# apollo510 register map
Vendor: Ambiq Micro; Series: Apollo; File version: 1.0
CPU: CM55 r1p1, little endian, MPU, FPU, double-precision FPU, DSP, I-cache, D-cache, VTOR, ITCM, DTCM, 4 interrupt priority bits, 0 interrupts, 8 SAU regions
Registers are 32-bit, read-write, reset 0x0 unless marked. A register's access mark holds for its fields unless they carry their own. Offsets are from the block's base; [hi:lo] are bit positions; {n}, {i} and the like mark numbered series; 'fields as' and 'values as' point back to an identical list.

## GPIO (part 7 of 7) — General Purpose IO
Base 0x40010000
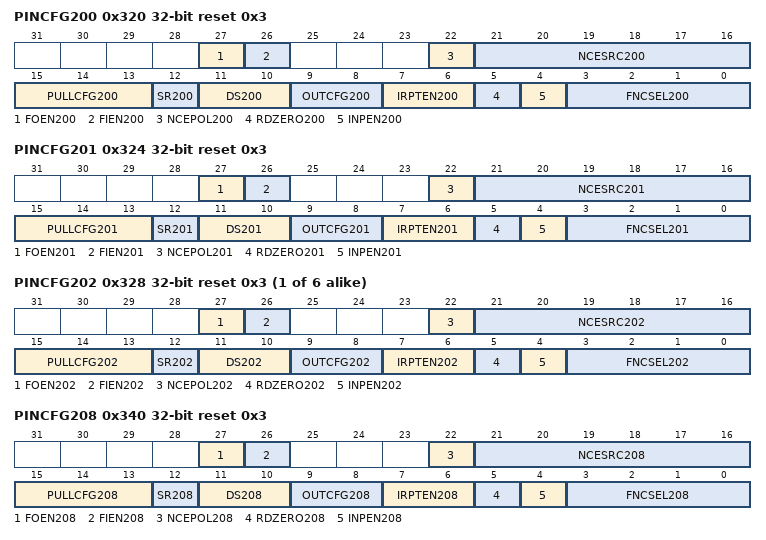
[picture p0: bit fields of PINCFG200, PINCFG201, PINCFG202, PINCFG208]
0x320 PINCFG200 reset 0x3 — Controls the operation of GPIO pin 200.
  [27] FOEN200 — Force output enable active regardless of function selected. Otherwise the selected function will enable the output only when needed
  [26] FIEN200 — Force input enable active regardless of function selected. Otherwise the selected function will enable the input only when needed
  [22] NCEPOL200 — Polarity select for NCE for GPIO 200
    0=LOW (Polarity is active low); 1=HIGH (Polarity is active high)
  [21:16] NCESRC200 — IOMSTR/MSPI N Chip Select 200, DISP control signals DE, CSX, and CS. Polarity is determined by CE_POLARITY field
    {v}=IOM0CE{v} (IOM 0 NCE {v} module) (v=0..3); {v}=IOM1CE{v-4} (IOM 1 NCE {v-4} module) (v=4..7); {v}=IOM2CE{v-8} (IOM 2 NCE {v-8} module) (v=8..11); {v}=IOM3CE{v-12} (IOM 3 NCE {v-12} module) (v=12..15); {v}=IOM4CE{v-16} (IOM 4 NCE {v-16} module) (v=16..19); {v}=IOM5CE{v-20} (IOM 5 NCE {v-20} module) (v=20..23); {v}=IOM6CE{v-24} (IOM 6 NCE {v-24} module) (v=24..27); {v}=IOM7CE{v-28} (IOM 7 NCE {v-28} module) (v=28..31); 48=DC_DPI_DE (DC DPI DE module); 49=DISP_CONT_CSX (DISP CONT CSX module); 50=DC_SPI_CS_N (DC SPI CS_N module); 51=DC_QSPI_CS_N (DC QSPI CS_N module); 52=DC_RESX (DC module RESX)
  [15:13] PULLCFG200 — Pullup/Pulldown configuration for GPIO 200
    0=DIS (No pullup or pulldown selected); 1=PD50K (50K Pulldown selected); 2=PU15K (1.5K Pullup selected); 3=PU6K (6K Pullup selected); 4=PU12K (12K Pullup selected); 5=PU24K (24K Pullup selected); 6=PU50K (50K Pullup selected); 7=PU100K (100K Pullup selected)
  [12] SR200 — Configure the slew rate
  [11:10] DS200 — Drive strength selection for GPIO 200
    0=0P1X (0.1x output driver selected); 1=0P5X (0.5x output driver selected); 2=0P75X (0.75x output driver selected); 3=1P0X (1.0x output driver selected)
  [9:8] OUTCFG200 — Pin IO mode selection for GPIO pin 200
    0=DIS (Output Disabled); 1=PUSHPULL (Output configured in push pull mode. Will drive 0 and 1 values on pin.); 2=OD (Output configured in open drain mode. Will only drive pin low, tristate otherwise.); 3=TS (Output configured in Tristate-able push pull mode. Will drive 0, 1 of HiZ on pin.)
  [7:6] IRPTEN200 — Interrupt enable for GPIO 200
    0=DIS (Interrupts are disabled for this GPIO); 1=INTFALL (Interrupts are enabled for falling edge transition on this GPIO); 2=INTRISE (Interrupts are enabled for rising edge transitions on this GPIO); 3=INTANY (Interrupts are enabled for any edge transition on this GPIO)
  [5] RDZERO200 — Return 0 for read data on GPIO 200
  [4] INPEN200 — Input enable for GPIO 200
  [3:0] FNCSEL200 — Function select for GPIO pin 200
    1=MNCE0_1 (MSPI Master 0 nCE 1 Signal); 2=MNCE0_0 (MSPI Master 0 nCE 0 Signal); 3=GPIO (General purpose I/O); 6=CT200 (Timer/Counter input or output; Selection of direction is done via CTIMER register settings.); 7=NCE200 (IOMSTR N Chip Select. Polarity is determined by CE_POLARITY field); 11=FPIO (Fast PIO)
0x324 PINCFG201 reset 0x3 — Controls the operation of GPIO pin 201.
  [27] FOEN201 — Force output enable active regardless of function selected. Otherwise the selected function will enable the output only when needed
  [26] FIEN201 — Force input enable active regardless of function selected. Otherwise the selected function will enable the input only when needed
  [22] NCEPOL201 — Polarity select for NCE for GPIO 201
    values as PINCFG200.NCEPOL200
  [21:16] NCESRC201 — IOMSTR/MSPI N Chip Select 201, DISP control signals DE, CSX, and CS. Polarity is determined by CE_POLARITY field
    values as PINCFG200.NCESRC200
  [15:13] PULLCFG201 — Pullup/Pulldown configuration for GPIO 201
    values as PINCFG200.PULLCFG200
  [12] SR201 — Configure the slew rate
  [11:10] DS201 — Drive strength selection for GPIO 201
    0=0P1X (0.1x output driver selected); 1=0P5X (0.5x output driver selected)
  [9:8] OUTCFG201 — Pin IO mode selection for GPIO pin 201
    values as PINCFG200.OUTCFG200
  [7:6] IRPTEN201 — Interrupt enable for GPIO 201
    values as PINCFG200.IRPTEN200
  [5] RDZERO201 — Return 0 for read data on GPIO 201
  [4] INPEN201 — Input enable for GPIO 201
  [3:0] FNCSEL201 — Function select for GPIO pin 201
    3=GPIO (General purpose I/O); 6=CT201 (Timer/Counter input or output; Selection of direction is done via CTIMER register settings.); 7=NCE201 (IOMSTR N Chip Select. Polarity is determined by CE_POLARITY field); 11=FPIO (Fast PIO)
{0x0+4i} PINCFG{i} reset 0x3 (i=202..207) — Controls the operation of GPIO pin {i}.
  [27] FOEN{i} — Force output enable active regardless of function selected. Otherwise the selected function will enable the output only when needed
  [26] FIEN{i} — Force input enable active regardless of function selected. Otherwise the selected function will enable the input only when needed
  [22] NCEPOL{i} — Polarity select for NCE for GPIO {i}
    values as PINCFG200.NCEPOL200
  [21:16] NCESRC{i} — IOMSTR/MSPI N Chip Select {i}, DISP control signals DE, CSX, and CS. Polarity is determined by CE_POLARITY field
    values as PINCFG200.NCESRC200
  [15:13] PULLCFG{i} — Pullup/Pulldown configuration for GPIO {i}
    values as PINCFG200.PULLCFG200
  [12] SR{i} — Configure the slew rate
  [11:10] DS{i} — Drive strength selection for GPIO {i}
    values as PINCFG201.DS201
  [9:8] OUTCFG{i} — Pin IO mode selection for GPIO pin {i}
    values as PINCFG200.OUTCFG200
  [7:6] IRPTEN{i} — Interrupt enable for GPIO {i}
    values as PINCFG200.IRPTEN200
  [5] RDZERO{i} — Return 0 for read data on GPIO {i}
  [4] INPEN{i} — Input enable for GPIO {i}
  [3:0] FNCSEL{i} — Function select for GPIO pin {i}
0x340 PINCFG208 reset 0x3 — Controls the operation of GPIO pin 208.
  [27] FOEN208 — Force output enable active regardless of function selected. Otherwise the selected function will enable the output only when needed
  [26] FIEN208 — Force input enable active regardless of function selected. Otherwise the selected function will enable the input only when needed
  [22] NCEPOL208 — Polarity select for NCE for GPIO 208
    values as PINCFG200.NCEPOL200
  [21:16] NCESRC208 — IOMSTR/MSPI N Chip Select 208, DISP control signals DE, CSX, and CS. Polarity is determined by CE_POLARITY field
    values as PINCFG200.NCESRC200
  [15:13] PULLCFG208 — Pullup/Pulldown configuration for GPIO 208
    values as PINCFG200.PULLCFG200
  [12] SR208 — Configure the slew rate
  [11:10] DS208 — Drive strength selection for GPIO 208
    values as PINCFG201.DS201
  [9:8] OUTCFG208 — Pin IO mode selection for GPIO pin 208
    values as PINCFG200.OUTCFG200
  [7:6] IRPTEN208 — Interrupt enable for GPIO 208
    values as PINCFG200.IRPTEN200
  [5] RDZERO208 — Return 0 for read data on GPIO 208
  [4] INPEN208 — Input enable for GPIO 208
  [3:0] FNCSEL208 — Function select for GPIO pin 208
    1=32KHzXT (32kHZ from analog); 3=GPIO (General purpose I/O); 6=CT208 (Timer/Counter input or output; Selection of direction is done via CTIMER register settings.); 7=NCE208 (IOMSTR N Chip Select. Polarity is determined by CE_POLARITY field); 11=FPIO (Fast PIO)
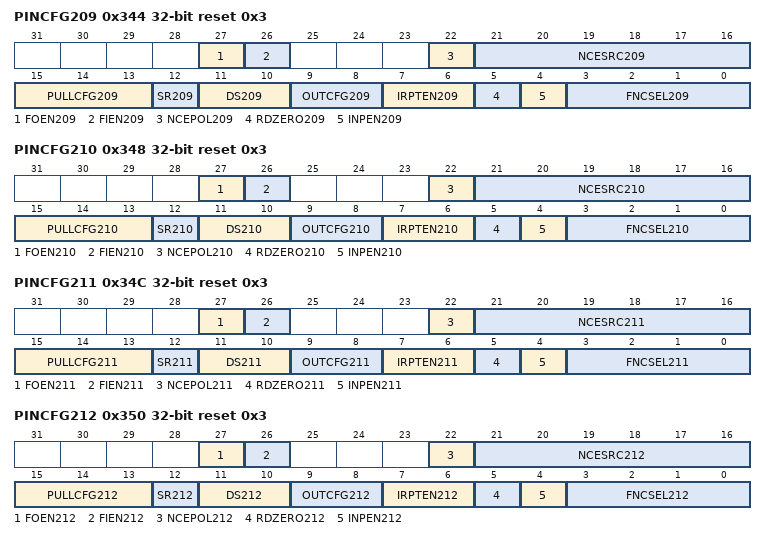
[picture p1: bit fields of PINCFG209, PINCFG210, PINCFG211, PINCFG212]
0x344 PINCFG209 reset 0x3 — Controls the operation of GPIO pin 209.
  [27] FOEN209 — Force output enable active regardless of function selected. Otherwise the selected function will enable the output only when needed
  [26] FIEN209 — Force input enable active regardless of function selected. Otherwise the selected function will enable the input only when needed
  [22] NCEPOL209 — Polarity select for NCE for GPIO 209
    values as PINCFG200.NCEPOL200
  [21:16] NCESRC209 — IOMSTR/MSPI N Chip Select 209, DISP control signals DE, CSX, and CS. Polarity is determined by CE_POLARITY field
    values as PINCFG200.NCESRC200
  [15:13] PULLCFG209 — Pullup/Pulldown configuration for GPIO 209
    values as PINCFG200.PULLCFG200
  [12] SR209 — Configure the slew rate
  [11:10] DS209 — Drive strength selection for GPIO 209
    values as PINCFG201.DS201
  [9:8] OUTCFG209 — Pin IO mode selection for GPIO pin 209
    values as PINCFG200.OUTCFG200
  [7:6] IRPTEN209 — Interrupt enable for GPIO 209
    values as PINCFG200.IRPTEN200
  [5] RDZERO209 — Return 0 for read data on GPIO 209
  [4] INPEN209 — Input enable for GPIO 209
  [3:0] FNCSEL209 — Function select for GPIO pin 209
    0=DISP_ENB (Display MiP Enable); 1=DISP_D1 (Display Data 1); 2=DBIB_CSX (Display DBI Chip Enable); 3=GPIO (General purpose I/O); 6=CT209 (Timer/Counter input or output; Selection of direction is done via CTIMER register settings.); 7=NCE209 (IOMSTR N Chip Select. Polarity is determined by CE_POLARITY field); 11=FPIO (Fast PIO)
0x348 PINCFG210 reset 0x3 — Controls the operation of GPIO pin 210.
  [27] FOEN210 — Force output enable active regardless of function selected. Otherwise the selected function will enable the output only when needed
  [26] FIEN210 — Force input enable active regardless of function selected. Otherwise the selected function will enable the input only when needed
  [22] NCEPOL210 — Polarity select for NCE for GPIO 210
    values as PINCFG200.NCEPOL200
  [21:16] NCESRC210 — IOMSTR/MSPI N Chip Select 210, DISP control signals DE, CSX, and CS. Polarity is determined by CE_POLARITY field
    values as PINCFG200.NCESRC200
  [15:13] PULLCFG210 — Pullup/Pulldown configuration for GPIO 210
    values as PINCFG200.PULLCFG200
  [12] SR210 — Configure the slew rate
  [11:10] DS210 — Drive strength selection for GPIO 210
    values as PINCFG201.DS201
  [9:8] OUTCFG210 — Pin IO mode selection for GPIO pin 210
    values as PINCFG200.OUTCFG200
  [7:6] IRPTEN210 — Interrupt enable for GPIO 210
    values as PINCFG200.IRPTEN200
  [5] RDZERO210 — Return 0 for read data on GPIO 210
  [4] INPEN210 — Input enable for GPIO 210
  [3:0] FNCSEL210 — Function select for GPIO pin 210
    0=DISP_XRST (Display MiP Reset); 1=DISP_D4 (Display Data 4); 2=DBIB_DCX (Display DBI Data/Command Select); 3=GPIO (General purpose I/O); 6=CT210 (Timer/Counter input or output; Selection of direction is done via CTIMER register settings.); 7=NCE210 (IOMSTR N Chip Select. Polarity is determined by CE_POLARITY field); 11=FPIO (Fast PIO)
0x34C PINCFG211 reset 0x3 — Controls the operation of GPIO pin 211.
  [27] FOEN211 — Force output enable active regardless of function selected. Otherwise the selected function will enable the output only when needed
  [26] FIEN211 — Force input enable active regardless of function selected. Otherwise the selected function will enable the input only when needed
  [22] NCEPOL211 — Polarity select for NCE for GPIO 211
    values as PINCFG200.NCEPOL200
  [21:16] NCESRC211 — IOMSTR/MSPI N Chip Select 211, DISP control signals DE, CSX, and CS. Polarity is determined by CE_POLARITY field
    values as PINCFG200.NCESRC200
  [15:13] PULLCFG211 — Pullup/Pulldown configuration for GPIO 211
    values as PINCFG200.PULLCFG200
  [12] SR211 — Configure the slew rate
  [11:10] DS211 — Drive strength selection for GPIO 211
    values as PINCFG201.DS201
  [9:8] OUTCFG211 — Pin IO mode selection for GPIO pin 211
    values as PINCFG200.OUTCFG200
  [7:6] IRPTEN211 — Interrupt enable for GPIO 211
    values as PINCFG200.IRPTEN200
  [5] RDZERO211 — Return 0 for read data on GPIO 211
  [4] INPEN211 — Input enable for GPIO 211
  [3:0] FNCSEL211 — Function select for GPIO pin 211
    0=DISP_R1 (Display MiP Red Bit 1); 1=DISP_D23 (Display Data 23); 2=DBIB_WRX (Display DBI Write); 3=GPIO (General purpose I/O); 6=CT211 (Timer/Counter input or output; Selection of direction is done via CTIMER register settings.); 7=NCE211 (IOMSTR N Chip Select. Polarity is determined by CE_POLARITY field); 11=FPIO (Fast PIO)
0x350 PINCFG212 reset 0x3 — Controls the operation of GPIO pin 212.
  [27] FOEN212 — Force output enable active regardless of function selected. Otherwise the selected function will enable the output only when needed
  [26] FIEN212 — Force input enable active regardless of function selected. Otherwise the selected function will enable the input only when needed
  [22] NCEPOL212 — Polarity select for NCE for GPIO 212
    values as PINCFG200.NCEPOL200
  [21:16] NCESRC212 — IOMSTR/MSPI N Chip Select 212, DISP control signals DE, CSX, and CS. Polarity is determined by CE_POLARITY field
    values as PINCFG200.NCESRC200
  [15:13] PULLCFG212 — Pullup/Pulldown configuration for GPIO 212
    values as PINCFG200.PULLCFG200
  [12] SR212 — Configure the slew rate
  [11:10] DS212 — Drive strength selection for GPIO 212
    values as PINCFG201.DS201
  [9:8] OUTCFG212 — Pin IO mode selection for GPIO pin 212
    values as PINCFG200.OUTCFG200
  [7:6] IRPTEN212 — Interrupt enable for GPIO 212
    values as PINCFG200.IRPTEN200
  [5] RDZERO212 — Return 0 for read data on GPIO 212
  [4] INPEN212 — Input enable for GPIO 212
  [3:0] FNCSEL212 — Function select for GPIO pin 212
    0=DISP_R2 (Display MiP Red Bit 2); 1=DISP_D22 (Display Data 22); 2=DBIB_RDX (Display DBI Read); 3=GPIO (General purpose I/O); 6=CT212 (Timer/Counter input or output; Selection of direction is done via CTIMER register settings.); 7=NCE212 (IOMSTR N Chip Select. Polarity is determined by CE_POLARITY field); 11=FPIO (Fast PIO)
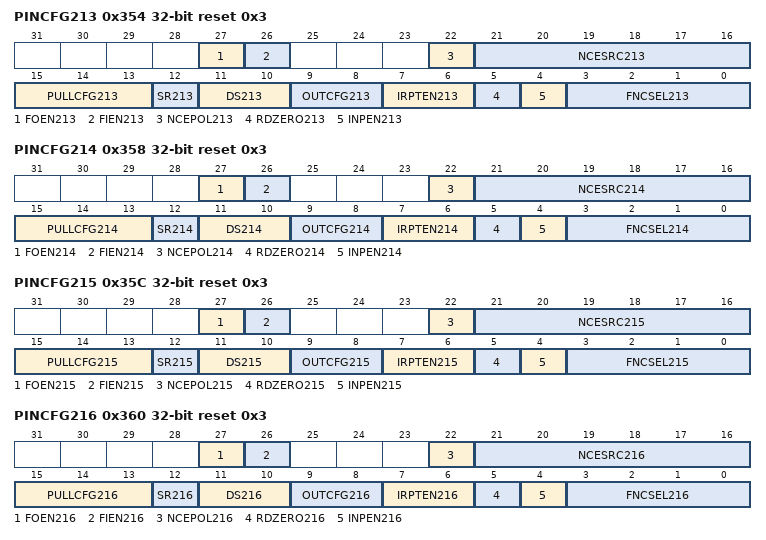
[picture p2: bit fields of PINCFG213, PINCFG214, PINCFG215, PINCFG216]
0x354 PINCFG213 reset 0x3 — Controls the operation of GPIO pin 213.
  [27] FOEN213 — Force output enable active regardless of function selected. Otherwise the selected function will enable the output only when needed
  [26] FIEN213 — Force input enable active regardless of function selected. Otherwise the selected function will enable the input only when needed
  [22] NCEPOL213 — Polarity select for NCE for GPIO 213
    values as PINCFG200.NCEPOL200
  [21:16] NCESRC213 — IOMSTR/MSPI N Chip Select 213, DISP control signals DE, CSX, and CS. Polarity is determined by CE_POLARITY field
    values as PINCFG200.NCESRC200
  [15:13] PULLCFG213 — Pullup/Pulldown configuration for GPIO 213
    values as PINCFG200.PULLCFG200
  [12] SR213 — Configure the slew rate
  [11:10] DS213 — Drive strength selection for GPIO 213
    values as PINCFG201.DS201
  [9:8] OUTCFG213 — Pin IO mode selection for GPIO pin 213
    values as PINCFG200.OUTCFG200
  [7:6] IRPTEN213 — Interrupt enable for GPIO 213
    values as PINCFG200.IRPTEN200
  [5] RDZERO213 — Return 0 for read data on GPIO 213
  [4] INPEN213 — Input enable for GPIO 213
  [3:0] FNCSEL213 — Function select for GPIO pin 213
    0=DISP_G1 (Display MiP Green Bit 1); 1=DISP_D21 (Display Data 21); 2=DBIB_D0 (Display DBI Data); 3=GPIO (General purpose I/O); 6=CT213 (Timer/Counter input or output; Selection of direction is done via CTIMER register settings.); 7=NCE213 (IOMSTR N Chip Select. Polarity is determined by CE_POLARITY field); 11=FPIO (Fast PIO)
0x358 PINCFG214 reset 0x3 — Controls the operation of GPIO pin 214.
  [27] FOEN214 — Force output enable active regardless of function selected. Otherwise the selected function will enable the output only when needed
  [26] FIEN214 — Force input enable active regardless of function selected. Otherwise the selected function will enable the input only when needed
  [22] NCEPOL214 — Polarity select for NCE for GPIO 214
    values as PINCFG200.NCEPOL200
  [21:16] NCESRC214 — IOMSTR/MSPI N Chip Select 214, DISP control signals DE, CSX, and CS. Polarity is determined by CE_POLARITY field
    values as PINCFG200.NCESRC200
  [15:13] PULLCFG214 — Pullup/Pulldown configuration for GPIO 214
    values as PINCFG200.PULLCFG200
  [12] SR214 — Configure the slew rate
  [11:10] DS214 — Drive strength selection for GPIO 214
    values as PINCFG201.DS201
  [9:8] OUTCFG214 — Pin IO mode selection for GPIO pin 214
    values as PINCFG200.OUTCFG200
  [7:6] IRPTEN214 — Interrupt enable for GPIO 214
    values as PINCFG200.IRPTEN200
  [5] RDZERO214 — Return 0 for read data on GPIO 214
  [4] INPEN214 — Input enable for GPIO 214
  [3:0] FNCSEL214 — Function select for GPIO pin 214
    0=DISP_G2 (Display MiP Green Bit 2); 1=DISP_D20 (Display Data 20); 2=DBIB_D1 (Display DBI Data); 3=GPIO (General purpose I/O); 6=CT214 (Timer/Counter input or output; Selection of direction is done via CTIMER register settings.); 7=NCE214 (IOMSTR N Chip Select. Polarity is determined by CE_POLARITY field); 11=FPIO (Fast PIO)
0x35C PINCFG215 reset 0x3 — Controls the operation of GPIO pin 215.
  [27] FOEN215 — Force output enable active regardless of function selected. Otherwise the selected function will enable the output only when needed
  [26] FIEN215 — Force input enable active regardless of function selected. Otherwise the selected function will enable the input only when needed
  [22] NCEPOL215 — Polarity select for NCE for GPIO 215
    values as PINCFG200.NCEPOL200
  [21:16] NCESRC215 — IOMSTR/MSPI N Chip Select 215, DISP control signals DE, CSX, and CS. Polarity is determined by CE_POLARITY field
    values as PINCFG200.NCESRC200
  [15:13] PULLCFG215 — Pullup/Pulldown configuration for GPIO 215
    values as PINCFG200.PULLCFG200
  [12] SR215 — Configure the slew rate
  [11:10] DS215 — Drive strength selection for GPIO 215
    values as PINCFG201.DS201
  [9:8] OUTCFG215 — Pin IO mode selection for GPIO pin 215
    values as PINCFG200.OUTCFG200
  [7:6] IRPTEN215 — Interrupt enable for GPIO 215
    values as PINCFG200.IRPTEN200
  [5] RDZERO215 — Return 0 for read data on GPIO 215
  [4] INPEN215 — Input enable for GPIO 215
  [3:0] FNCSEL215 — Function select for GPIO pin 215
    0=DISP_B1 (Display MiP Blue Bit 1); 1=DISP_D19 (Display Data 19); 2=DBIB_D2 (Display DBI Data); 3=GPIO (General purpose I/O); 6=CT215 (Timer/Counter input or output; Selection of direction is done via CTIMER register settings.); 7=NCE215 (IOMSTR N Chip Select. Polarity is determined by CE_POLARITY field); 11=FPIO (Fast PIO)
0x360 PINCFG216 reset 0x3 — Controls the operation of GPIO pin 216.
  [27] FOEN216 — Force output enable active regardless of function selected. Otherwise the selected function will enable the output only when needed
  [26] FIEN216 — Force input enable active regardless of function selected. Otherwise the selected function will enable the input only when needed
  [22] NCEPOL216 — Polarity select for NCE for GPIO 216
    values as PINCFG200.NCEPOL200
  [21:16] NCESRC216 — IOMSTR/MSPI N Chip Select 216, DISP control signals DE, CSX, and CS. Polarity is determined by CE_POLARITY field
    values as PINCFG200.NCESRC200
  [15:13] PULLCFG216 — Pullup/Pulldown configuration for GPIO 216
    values as PINCFG200.PULLCFG200
  [12] SR216 — Configure the slew rate
  [11:10] DS216 — Drive strength selection for GPIO 216
    values as PINCFG201.DS201
  [9:8] OUTCFG216 — Pin IO mode selection for GPIO pin 216
    values as PINCFG200.OUTCFG200
  [7:6] IRPTEN216 — Interrupt enable for GPIO 216
    values as PINCFG200.IRPTEN200
  [5] RDZERO216 — Return 0 for read data on GPIO 216
  [4] INPEN216 — Input enable for GPIO 216
  [3:0] FNCSEL216 — Function select for GPIO pin 216
    0=DISP_B2 (Display MiP Blue Bit 2); 1=DISP_D18 (Display Data 18); 2=DBIB_D3 (Display DBI Data); 3=GPIO (General purpose I/O); 6=CT216 (Timer/Counter input or output; Selection of direction is done via CTIMER register settings.); 7=NCE216 (IOMSTR N Chip Select. Polarity is determined by CE_POLARITY field); 11=FPIO (Fast PIO)
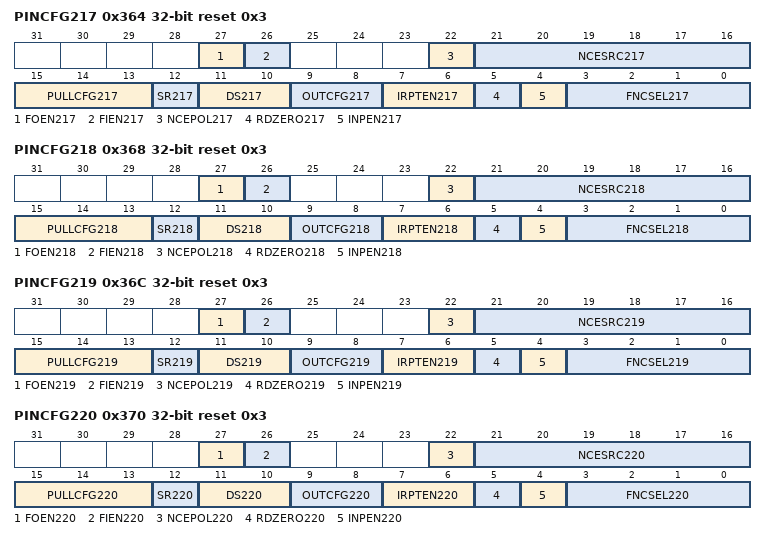
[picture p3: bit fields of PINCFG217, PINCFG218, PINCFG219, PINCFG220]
0x364 PINCFG217 reset 0x3 — Controls the operation of GPIO pin 217.
  [27] FOEN217 — Force output enable active regardless of function selected. Otherwise the selected function will enable the output only when needed
  [26] FIEN217 — Force input enable active regardless of function selected. Otherwise the selected function will enable the input only when needed
  [22] NCEPOL217 — Polarity select for NCE for GPIO 217
    values as PINCFG200.NCEPOL200
  [21:16] NCESRC217 — IOMSTR/MSPI N Chip Select 217, DISP control signals DE, CSX, and CS. Polarity is determined by CE_POLARITY field
    values as PINCFG200.NCESRC200
  [15:13] PULLCFG217 — Pullup/Pulldown configuration for GPIO 217
    values as PINCFG200.PULLCFG200
  [12] SR217 — Configure the slew rate
  [11:10] DS217 — Drive strength selection for GPIO 217
    values as PINCFG201.DS201
  [9:8] OUTCFG217 — Pin IO mode selection for GPIO pin 217
    values as PINCFG200.OUTCFG200
  [7:6] IRPTEN217 — Interrupt enable for GPIO 217
    values as PINCFG200.IRPTEN200
  [5] RDZERO217 — Return 0 for read data on GPIO 217
  [4] INPEN217 — Input enable for GPIO 217
  [3:0] FNCSEL217 — Function select for GPIO pin 217
    0=DISP_HST (Display MiP HSYNC); 1=DISP_HS (Display RGB HSYNC); 2=DBIB_D4 (Display DBI Data); 3=GPIO (General purpose I/O); 6=CT217 (Timer/Counter input or output; Selection of direction is done via CTIMER register settings.); 7=NCE217 (IOMSTR N Chip Select. Polarity is determined by CE_POLARITY field); 11=FPIO (Fast PIO)
0x368 PINCFG218 reset 0x3 — Controls the operation of GPIO pin 218.
  [27] FOEN218 — Force output enable active regardless of function selected. Otherwise the selected function will enable the output only when needed
  [26] FIEN218 — Force input enable active regardless of function selected. Otherwise the selected function will enable the input only when needed
  [22] NCEPOL218 — Polarity select for NCE for GPIO 218
    values as PINCFG200.NCEPOL200
  [21:16] NCESRC218 — IOMSTR/MSPI N Chip Select 218, DISP control signals DE, CSX, and CS. Polarity is determined by CE_POLARITY field
    values as PINCFG200.NCESRC200
  [15:13] PULLCFG218 — Pullup/Pulldown configuration for GPIO 218
    values as PINCFG200.PULLCFG200
  [12] SR218 — Configure the slew rate
  [11:10] DS218 — Drive strength selection for GPIO 218
    values as PINCFG201.DS201
  [9:8] OUTCFG218 — Pin IO mode selection for GPIO pin 218
    values as PINCFG200.OUTCFG200
  [7:6] IRPTEN218 — Interrupt enable for GPIO 218
    values as PINCFG200.IRPTEN200
  [5] RDZERO218 — Return 0 for read data on GPIO 218
  [4] INPEN218 — Input enable for GPIO 218
  [3:0] FNCSEL218 — Function select for GPIO pin 218
    0=DISP_VST (Display MiP VSYNC); 1=DISP_VS (Display RGB VSYNC); 2=DBIB_D5 (Display DBI Data); 3=GPIO (General purpose I/O); 6=CT218 (Timer/Counter input or output; Selection of direction is done via CTIMER register settings.); 7=NCE218 (IOMSTR N Chip Select. Polarity is determined by CE_POLARITY field); 11=FPIO (Fast PIO)
0x36C PINCFG219 reset 0x3 — Controls the operation of GPIO pin 219.
  [27] FOEN219 — Force output enable active regardless of function selected. Otherwise the selected function will enable the output only when needed
  [26] FIEN219 — Force input enable active regardless of function selected. Otherwise the selected function will enable the input only when needed
  [22] NCEPOL219 — Polarity select for NCE for GPIO 219
    values as PINCFG200.NCEPOL200
  [21:16] NCESRC219 — IOMSTR/MSPI N Chip Select 219, DISP control signals DE, CSX, and CS. Polarity is determined by CE_POLARITY field
    values as PINCFG200.NCESRC200
  [15:13] PULLCFG219 — Pullup/Pulldown configuration for GPIO 219
    values as PINCFG200.PULLCFG200
  [12] SR219 — Configure the slew rate
  [11:10] DS219 — Drive strength selection for GPIO 219
    values as PINCFG201.DS201
  [9:8] OUTCFG219 — Pin IO mode selection for GPIO pin 219
    values as PINCFG200.OUTCFG200
  [7:6] IRPTEN219 — Interrupt enable for GPIO 219
    values as PINCFG200.IRPTEN200
  [5] RDZERO219 — Return 0 for read data on GPIO 219
  [4] INPEN219 — Input enable for GPIO 219
  [3:0] FNCSEL219 — Function select for GPIO pin 219
    0=DISP_HCK (Display MiP HCLK); 1=DISP_D3 (Display Data 3); 2=DBIB_D6 (Display DBI Data); 3=GPIO (General purpose I/O); 6=CT219 (Timer/Counter input or output; Selection of direction is done via CTIMER register settings.); 7=NCE219 (IOMSTR N Chip Select. Polarity is determined by CE_POLARITY field); 11=FPIO (Fast PIO)
0x370 PINCFG220 reset 0x3 — Controls the operation of GPIO pin 220.
  [27] FOEN220 — Force output enable active regardless of function selected. Otherwise the selected function will enable the output only when needed
  [26] FIEN220 — Force input enable active regardless of function selected. Otherwise the selected function will enable the input only when needed
  [22] NCEPOL220 — Polarity select for NCE for GPIO 220
    values as PINCFG200.NCEPOL200
  [21:16] NCESRC220 — IOMSTR/MSPI N Chip Select 220, DISP control signals DE, CSX, and CS. Polarity is determined by CE_POLARITY field
    values as PINCFG200.NCESRC200
  [15:13] PULLCFG220 — Pullup/Pulldown configuration for GPIO 220
    values as PINCFG200.PULLCFG200
  [12] SR220 — Configure the slew rate
  [11:10] DS220 — Drive strength selection for GPIO 220
    values as PINCFG201.DS201
  [9:8] OUTCFG220 — Pin IO mode selection for GPIO pin 220
    values as PINCFG200.OUTCFG200
  [7:6] IRPTEN220 — Interrupt enable for GPIO 220
    values as PINCFG200.IRPTEN200
  [5] RDZERO220 — Return 0 for read data on GPIO 220
  [4] INPEN220 — Input enable for GPIO 220
  [3:0] FNCSEL220 — Function select for GPIO pin 220
    0=DISP_VCK (Display MiP VCLK); 1=DISP_D0 (Display Data 0); 2=DBIB_D7 (Display DBI Data); 3=GPIO (General purpose I/O); 6=CT220 (Timer/Counter input or output; Selection of direction is done via CTIMER register settings.); 7=NCE220 (IOMSTR N Chip Select. Polarity is determined by CE_POLARITY field); 11=FPIO (Fast PIO)
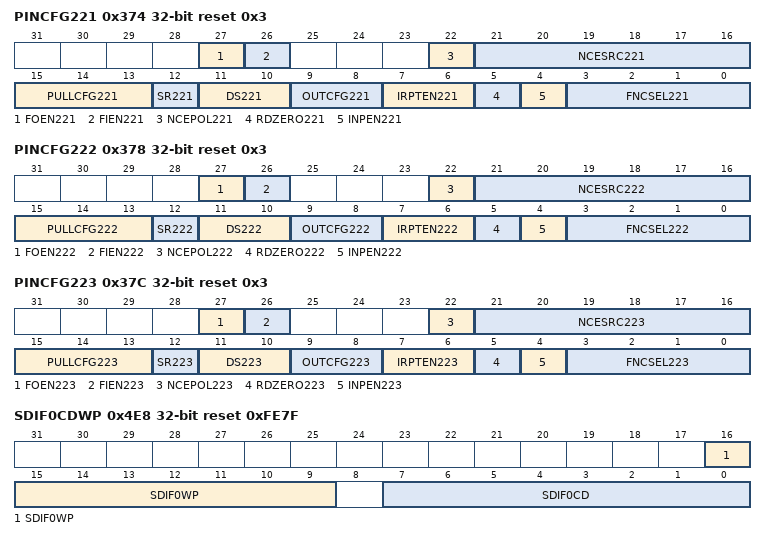
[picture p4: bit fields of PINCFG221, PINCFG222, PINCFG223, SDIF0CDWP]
0x374 PINCFG221 reset 0x3 — Controls the operation of GPIO pin 221.
  [27] FOEN221 — Force output enable active regardless of function selected. Otherwise the selected function will enable the output only when needed
  [26] FIEN221 — Force input enable active regardless of function selected. Otherwise the selected function will enable the input only when needed
  [22] NCEPOL221 — Polarity select for NCE for GPIO 221
    values as PINCFG200.NCEPOL200
  [21:16] NCESRC221 — IOMSTR/MSPI N Chip Select 221, DISP control signals DE, CSX, and CS. Polarity is determined by CE_POLARITY field
    values as PINCFG200.NCESRC200
  [15:13] PULLCFG221 — Pullup/Pulldown configuration for GPIO 221
    values as PINCFG200.PULLCFG200
  [12] SR221 — Configure the slew rate
  [11:10] DS221 — Drive strength selection for GPIO 221
    values as PINCFG201.DS201
  [9:8] OUTCFG221 — Pin IO mode selection for GPIO pin 221
    values as PINCFG200.OUTCFG200
  [7:6] IRPTEN221 — Interrupt enable for GPIO 221
    values as PINCFG200.IRPTEN200
  [5] RDZERO221 — Return 0 for read data on GPIO 221
  [4] INPEN221 — Input enable for GPIO 221
  [3:0] FNCSEL221 — Function select for GPIO pin 221
    1=DISP_D2 (Display Data 2); 3=GPIO (General purpose I/O); 6=CT221 (Timer/Counter input or output; Selection of direction is done via CTIMER register settings.); 7=NCE221 (IOMSTR N Chip Select. Polarity is determined by CE_POLARITY field); 11=FPIO (Fast PIO)
0x378 PINCFG222 reset 0x3 — Controls the operation of GPIO pin 222.
  [27] FOEN222 — Force output enable active regardless of function selected. Otherwise the selected function will enable the output only when needed
  [26] FIEN222 — Force input enable active regardless of function selected. Otherwise the selected function will enable the input only when needed
  [22] NCEPOL222 — Polarity select for NCE for GPIO 222
    values as PINCFG200.NCEPOL200
  [21:16] NCESRC222 — IOMSTR/MSPI N Chip Select 222, DISP control signals DE, CSX, and CS. Polarity is determined by CE_POLARITY field
    values as PINCFG200.NCESRC200
  [15:13] PULLCFG222 — Pullup/Pulldown configuration for GPIO 222
    values as PINCFG200.PULLCFG200
  [12] SR222 — Configure the slew rate
  [11:10] DS222 — Drive strength selection for GPIO 222
    values as PINCFG201.DS201
  [9:8] OUTCFG222 — Pin IO mode selection for GPIO pin 222
    values as PINCFG200.OUTCFG200
  [7:6] IRPTEN222 — Interrupt enable for GPIO 222
    values as PINCFG200.IRPTEN200
  [5] RDZERO222 — Return 0 for read data on GPIO 222
  [4] INPEN222 — Input enable for GPIO 222
  [3:0] FNCSEL222 — Function select for GPIO pin 222
    1=DISP_D13 (Display Data 13); 3=GPIO (General purpose I/O); 6=CT222 (Timer/Counter input or output; Selection of direction is done via CTIMER register settings.); 7=NCE222 (IOMSTR N Chip Select. Polarity is determined by CE_POLARITY field); 9=MNCE0_0 (MSPI Master 0 nCE 0 Signal); 11=FPIO (Fast PIO)
0x37C PINCFG223 reset 0x3 — Controls the operation of GPIO pin 223.
  [27] FOEN223 — Force output enable active regardless of function selected. Otherwise the selected function will enable the output only when needed
  [26] FIEN223 — Force input enable active regardless of function selected. Otherwise the selected function will enable the input only when needed
  [22] NCEPOL223 — Polarity select for NCE for GPIO 223
    values as PINCFG200.NCEPOL200
  [21:16] NCESRC223 — IOMSTR/MSPI N Chip Select 223, DISP control signals DE, CSX, and CS. Polarity is determined by CE_POLARITY field
    values as PINCFG200.NCESRC200
  [15:13] PULLCFG223 — Pullup/Pulldown configuration for GPIO 223
    values as PINCFG200.PULLCFG200
  [12] SR223 — Configure the slew rate
  [11:10] DS223 — Drive strength selection for GPIO 223
    values as PINCFG201.DS201
  [9:8] OUTCFG223 — Pin IO mode selection for GPIO pin 223
    values as PINCFG200.OUTCFG200
  [7:6] IRPTEN223 — Interrupt enable for GPIO 223
    values as PINCFG200.IRPTEN200
  [5] RDZERO223 — Return 0 for read data on GPIO 223
  [4] INPEN223 — Input enable for GPIO 223
  [3:0] FNCSEL223 — Function select for GPIO pin 223
    1=DISP_D14 (Display Data 14); 3=GPIO (General purpose I/O); 6=CT223 (Timer/Counter input or output; Selection of direction is done via CTIMER register settings.); 7=NCE223 (IOMSTR N Chip Select. Polarity is determined by CE_POLARITY field); 9=MNCE3_0 (MSPI Master 3 nCE 0 Signal); 11=FPIO (Fast PIO)
0x400 PADKEY — Lock state of the PINCFG and GPIO configuration registers. Write a value of 0x73 to unlock write access to the PAD and GPIO.
  [31:0] PADKEY — Key register value.
    115=Key (Key value to unlock the register.)
{0x404+4i} RD{i} (i=0..6) — GPIO Input {i} ({32i+31}-{32i})
  [31:0] RD{i} — GPIO{32i+31}-{32i} Reads pin state - read only. Returns the pad pin state for pins {32i+31}-{32i} if the PINCFG's input enable (INPEN) is active and RDZERO is inactive.
{0x420+4i} WT{i} (i=0..6) — GPIO Output {i} ({32i+31}-{32i})
  [31:0] WT{i} — GPIO{32i+31}-{32i} Reads or writes pin state. Writes of 1 bits set output pad signal if the GPIO is enabled for output. Reads return status, including sets/clears through the WTS and WTC registers.
{0x43C+4i} WTS{i} (i=0..6) — GPIO Output Set {i} ({32i+31}-{32i})
  [31:0] WTS{i} — GPIO{32i+31}-{32i} Sets pin state. Writing a 1 to any bit sets the corresponding bit in the WT register if the GPIO is enabled for output. Writing a value of 0 has no effect on the corresponding bit in the WT register. Status reads should be made via the WT Register.
{0x458+4i} WTC{i} (i=0..6) — GPIO Output Clear {i} ({32i+31}-{32i})
  [31:0] WTC{i} — GPIO{32i+31}-{32i} Clears pin state. Writing a 1 to any bit clears the corresponding bit in the WT register if the GPIO is enabled for output. Writing a value of 0 has no effect on the corresponding bit in the WT register. Status reads should be made via the WT Register.
{0x474+4i} EN{i} (i=0..6) — GPIO Enable {i} ({32i+31}-{32i})
  [31:0] EN{i} — GPIO{32i+31}-{32i} Enables tri-state pin output. Writing a 1 to any bit enables, and writing a 0 to any bit disables, the output for the corresponding GPIO. Reads return output enable/disable status of GPIO.
{0x490+4i} ENS{i} (i=0..6) — GPIO Enable Set {i} ({32i+31}-{32i})
  [31:0] ENS{i} — GPIO{32i+31}-{32i} Sets pin tri-state output enables. Writing a 1 to any bit sets the corresponding bit in the EN register. Writing a value of 0 has no effect on the corresponding bit in the EN register. Status reads should be made to the EN Register.
{0x4AC+4i} ENC{i} (i=0..6) — GPIO Enable Clear {i} ({32i+31}-{32i})
  [31:0] ENC{i} — GPIO{32i+31}-{32i} Clears pin tri-state output enables. Writing a 1 to any bit clears the corresponding bit in the EN register. Writing a value of 0 has no effect on the corresponding bit in the EN register. Status reads should be made to the EN Register.
{0x4C8+4i} IOM{i}IRQ reset 0xFF (i=0..7) — IOM{i} IRQ select for flow control.
  [7:0] IOM{i}IRQ — IOM{i} IRQ pad select.
0x4E8 SDIF0CDWP reset 0xFE7F — SDIF0 CD and WP Select.
  [16:9] SDIF0WP — SDIF0 WP pad select.
  [7:0] SDIF0CD — SDIF0 CD pad select
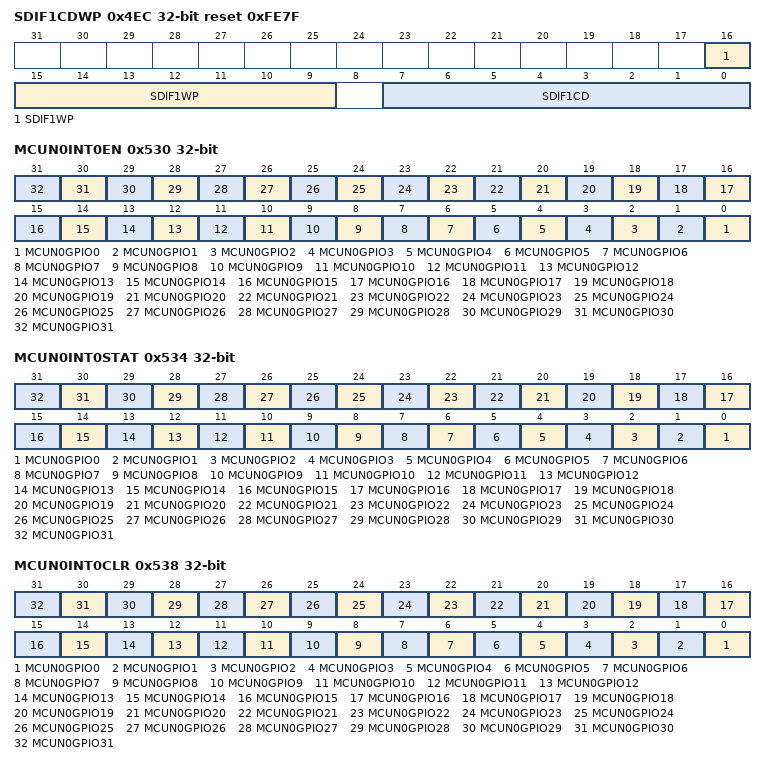
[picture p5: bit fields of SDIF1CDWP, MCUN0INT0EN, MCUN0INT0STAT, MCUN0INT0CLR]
0x4EC SDIF1CDWP reset 0xFE7F — SDIF1 CD and WP Select.
  [16:9] SDIF1WP — SDIF1 WP pad select.
  [7:0] SDIF1CD — SDIF1 CD pad select
0x4F0 OBSDATA — GPIO Observation mode sample
  [15:0] OBSDATA — Sample of the data output on the GPIO observation port. May have async sampling issues, as the data is not synronized to the read operation. Intended for debug purposes only.
{0x4F4+4i} IEOBS{i} (i=0..6) — Read only. Reflects the value of the input enable signals for pads {32i+31}-{32i} sent to the pad.
  [31:0] IEDATA{i} — 1 indicates the input_en is active and the value of the pad will be trasmitted to the internal logic within the device.
{0x510+4i} OEOBS{i} (i=0..6) — Read only. Reflects the value of the output enable signals for pads {32i+31}-{32i} sent to the pad.
  [31:0] OEDATA{i} — The signal is negative active, and a value of 0 indicates the output_en_ is active and the MCU will be driving the pad.
0x530 MCUN0INT0EN — Set bits in this register to allow this module to generate the corresponding interrupt.
  [n] MCUN0GPIO{n} (n=0..31) — GPIO{n} MCU N0-priority interrupt
0x534 MCUN0INT0STAT — Read bits from this register to discover the cause of a recent interrupt.
  [n] MCUN0GPIO{n} (n=0..31) — GPIO{n} MCU N0-priority interrupt
0x538 MCUN0INT0CLR — Write a 1 to a bit in this register to clear the interrupt status associated with that bit.
  [n] MCUN0GPIO{n} (n=0..31) — GPIO{n} MCU N0-priority interrupt
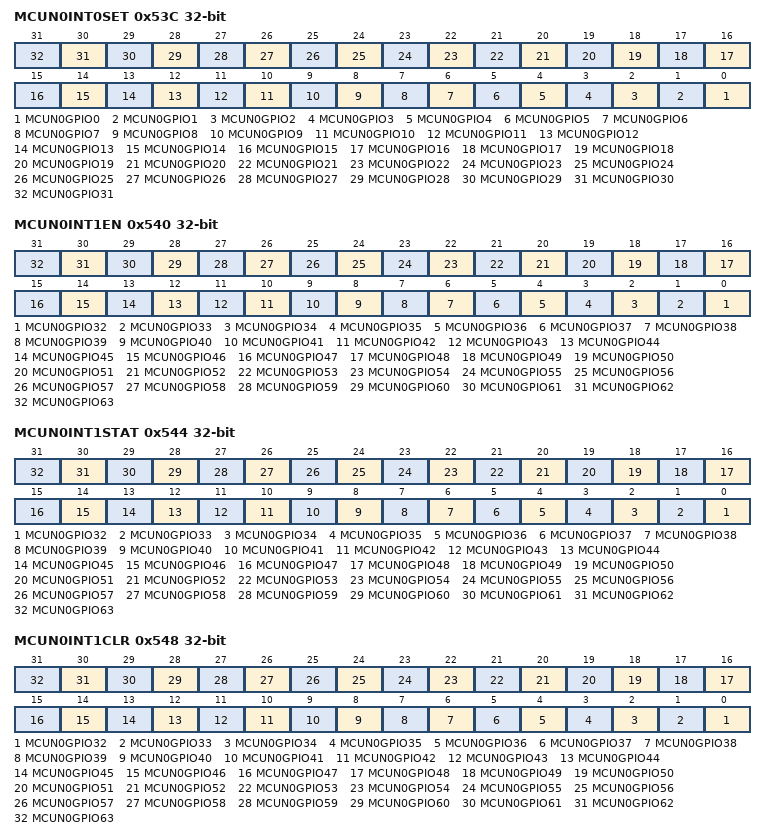
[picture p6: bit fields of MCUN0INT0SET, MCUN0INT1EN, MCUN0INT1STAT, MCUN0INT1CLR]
0x53C MCUN0INT0SET — Write a 1 to a bit in this register to instantly generate an interrupt from this module. (Generally used for testing purposes).
  [n] MCUN0GPIO{n} (n=0..31) — GPIO{n} MCU N0-priority interrupt
0x540 MCUN0INT1EN — Set bits in this register to allow this module to generate the corresponding interrupt.
  [n-32] MCUN0GPIO{n} (n=32..63) — GPIO{n} MCU N0-priority interrupt
0x544 MCUN0INT1STAT — Read bits from this register to discover the cause of a recent interrupt.
  [n-32] MCUN0GPIO{n} (n=32..63) — GPIO{n} MCU N0-priority interrupt
0x548 MCUN0INT1CLR — Write a 1 to a bit in this register to clear the interrupt status associated with that bit.
  [n-32] MCUN0GPIO{n} (n=32..63) — GPIO{n} MCU N0-priority interrupt
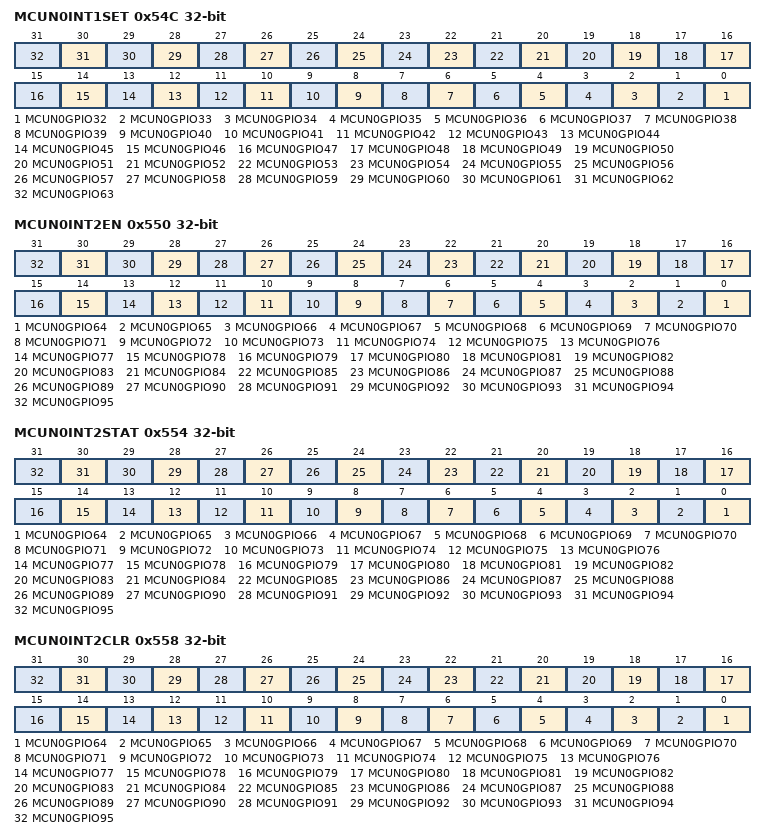
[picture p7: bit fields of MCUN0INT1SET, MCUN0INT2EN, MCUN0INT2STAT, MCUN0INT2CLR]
0x54C MCUN0INT1SET — Write a 1 to a bit in this register to instantly generate an interrupt from this module. (Generally used for testing purposes).
  [n-32] MCUN0GPIO{n} (n=32..63) — GPIO{n} MCU N0-priority interrupt
0x550 MCUN0INT2EN — Set bits in this register to allow this module to generate the corresponding interrupt.
  [n-64] MCUN0GPIO{n} (n=64..95) — GPIO{n} MCU N0-priority interrupt
0x554 MCUN0INT2STAT — Read bits from this register to discover the cause of a recent interrupt.
  [n-64] MCUN0GPIO{n} (n=64..95) — GPIO{n} MCU N0-priority interrupt
0x558 MCUN0INT2CLR — Write a 1 to a bit in this register to clear the interrupt status associated with that bit.
  [n-64] MCUN0GPIO{n} (n=64..95) — GPIO{n} MCU N0-priority interrupt
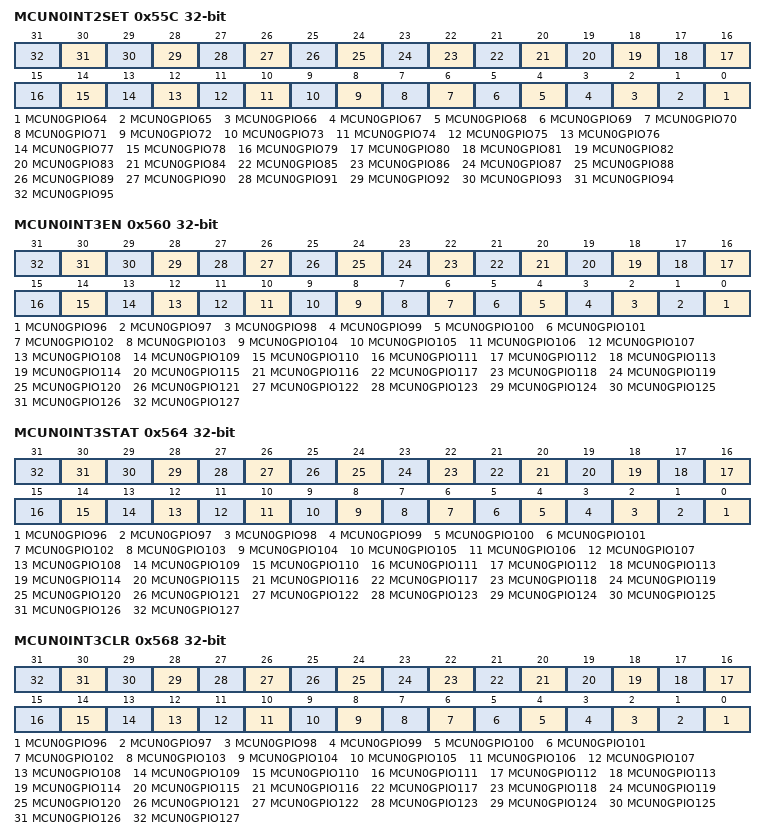
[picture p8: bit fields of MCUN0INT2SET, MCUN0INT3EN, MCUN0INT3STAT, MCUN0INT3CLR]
0x55C MCUN0INT2SET — Write a 1 to a bit in this register to instantly generate an interrupt from this module. (Generally used for testing purposes).
  [n-64] MCUN0GPIO{n} (n=64..95) — GPIO{n} MCU N0-priority interrupt
0x560 MCUN0INT3EN — Set bits in this register to allow this module to generate the corresponding interrupt.
  [n-96] MCUN0GPIO{n} (n=96..127) — GPIO{n} MCU N0-priority interrupt
0x564 MCUN0INT3STAT — Read bits from this register to discover the cause of a recent interrupt.
  [n-96] MCUN0GPIO{n} (n=96..127) — GPIO{n} MCU N0-priority interrupt
0x568 MCUN0INT3CLR — Write a 1 to a bit in this register to clear the interrupt status associated with that bit.
  [n-96] MCUN0GPIO{n} (n=96..127) — GPIO{n} MCU N0-priority interrupt
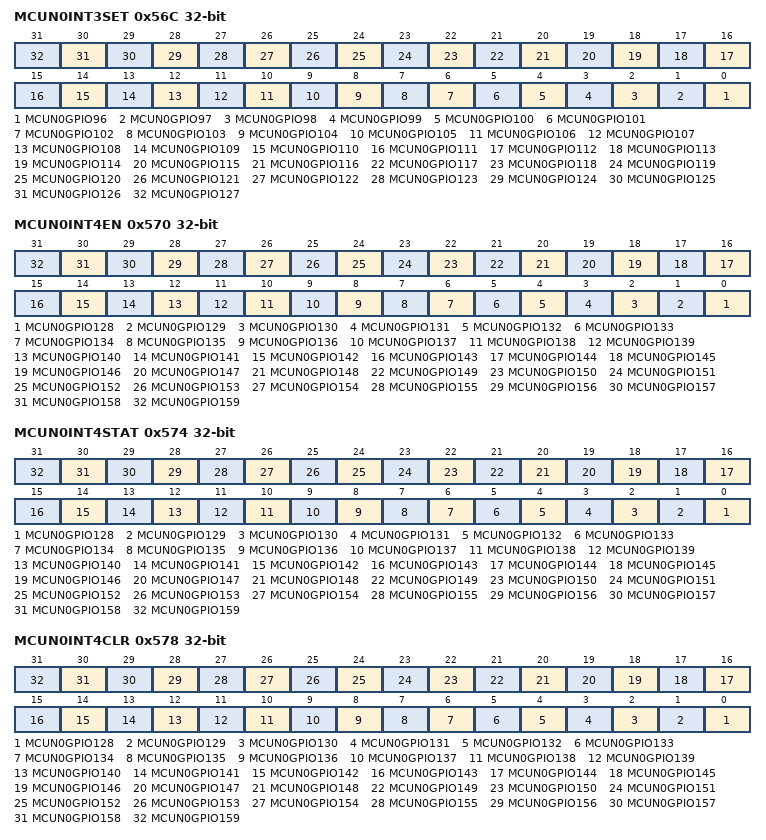
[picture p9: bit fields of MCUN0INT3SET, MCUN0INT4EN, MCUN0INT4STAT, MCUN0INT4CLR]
0x56C MCUN0INT3SET — Write a 1 to a bit in this register to instantly generate an interrupt from this module. (Generally used for testing purposes).
  [n-96] MCUN0GPIO{n} (n=96..127) — GPIO{n} MCU N0-priority interrupt
0x570 MCUN0INT4EN — Set bits in this register to allow this module to generate the corresponding interrupt.
  [n-128] MCUN0GPIO{n} (n=128..159) — GPIO{n} MCU N0-priority interrupt
0x574 MCUN0INT4STAT — Read bits from this register to discover the cause of a recent interrupt.
  fields as MCUN0INT4EN
0x578 MCUN0INT4CLR — Write a 1 to a bit in this register to clear the interrupt status associated with that bit.
  fields as MCUN0INT4EN
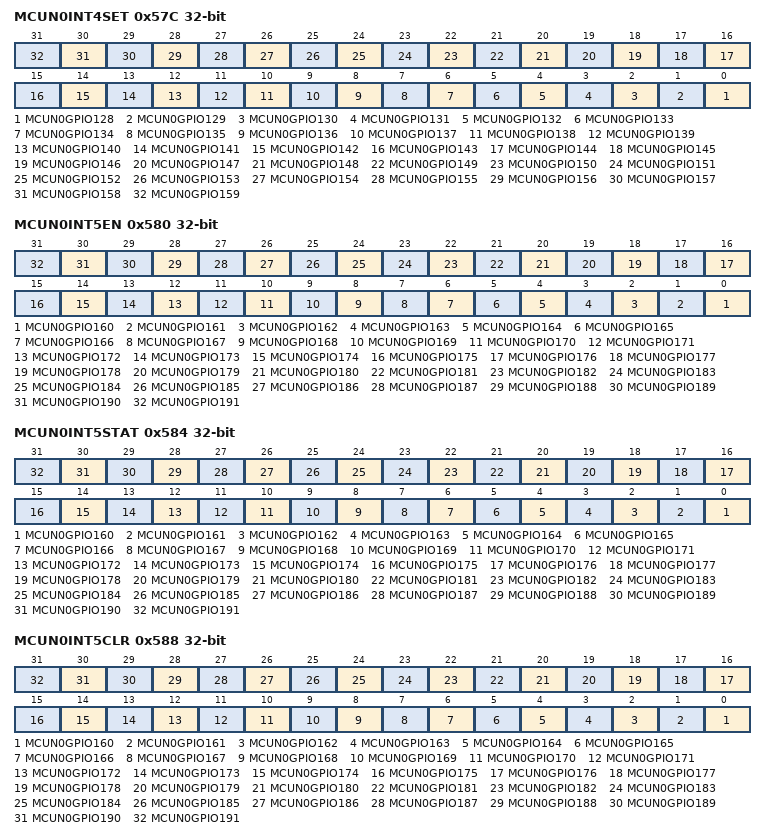
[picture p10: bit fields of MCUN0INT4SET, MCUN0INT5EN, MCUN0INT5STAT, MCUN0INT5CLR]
0x57C MCUN0INT4SET — Write a 1 to a bit in this register to instantly generate an interrupt from this module. (Generally used for testing purposes).
  fields as MCUN0INT4EN
0x580 MCUN0INT5EN — Set bits in this register to allow this module to generate the corresponding interrupt.
  [n-160] MCUN0GPIO{n} (n=160..191) — GPIO{n} MCU N0-priority interrupt
0x584 MCUN0INT5STAT — Read bits from this register to discover the cause of a recent interrupt.
  fields as MCUN0INT5EN
0x588 MCUN0INT5CLR — Write a 1 to a bit in this register to clear the interrupt status associated with that bit.
  fields as MCUN0INT5EN
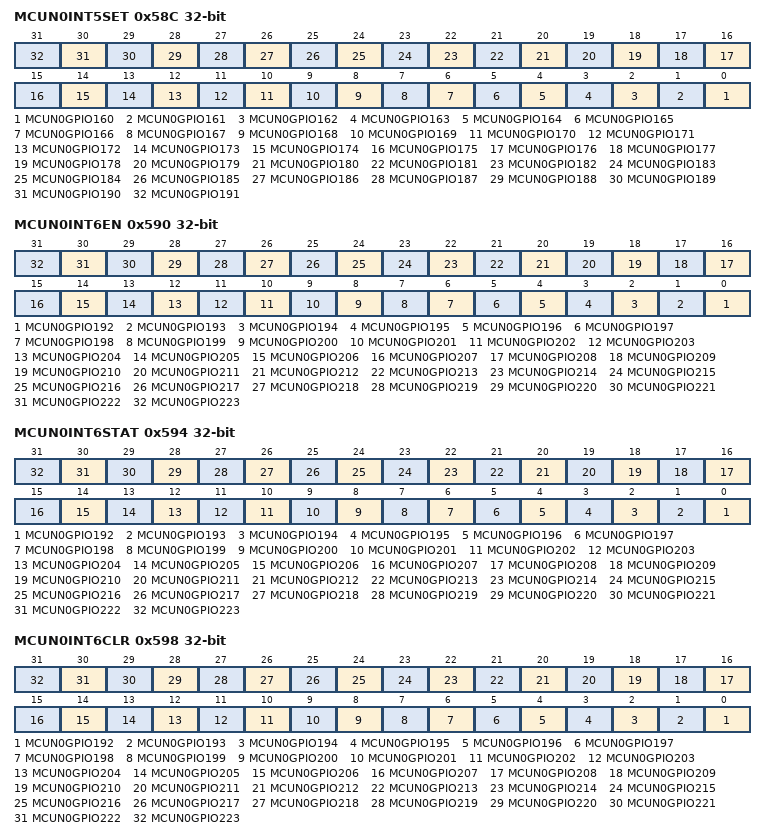
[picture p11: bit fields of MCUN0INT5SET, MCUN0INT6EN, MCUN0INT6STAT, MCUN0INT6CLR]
0x58C MCUN0INT5SET — Write a 1 to a bit in this register to instantly generate an interrupt from this module. (Generally used for testing purposes).
  fields as MCUN0INT5EN
0x590 MCUN0INT6EN — Set bits in this register to allow this module to generate the corresponding interrupt.
  [n-192] MCUN0GPIO{n} (n=192..223) — GPIO{n} MCU N0-priority interrupt
0x594 MCUN0INT6STAT — Read bits from this register to discover the cause of a recent interrupt.
  fields as MCUN0INT6EN
0x598 MCUN0INT6CLR — Write a 1 to a bit in this register to clear the interrupt status associated with that bit.
  fields as MCUN0INT6EN
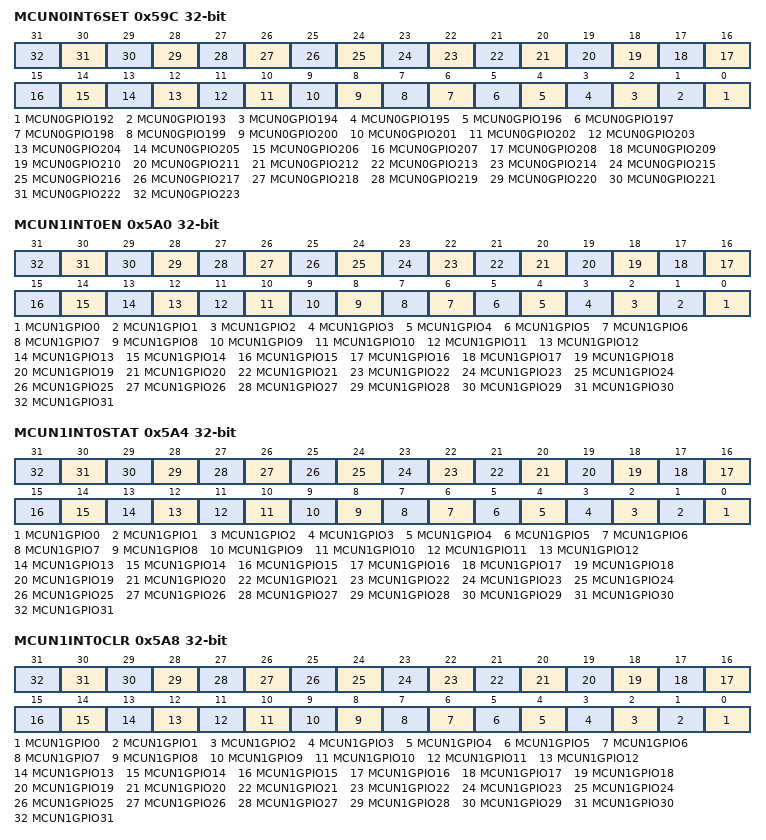
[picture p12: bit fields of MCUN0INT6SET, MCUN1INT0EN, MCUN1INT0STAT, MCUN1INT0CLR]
0x59C MCUN0INT6SET — Write a 1 to a bit in this register to instantly generate an interrupt from this module. (Generally used for testing purposes).
  fields as MCUN0INT6EN
0x5A0 MCUN1INT0EN — Set bits in this register to allow this module to generate the corresponding interrupt.
  [n] MCUN1GPIO{n} (n=0..31) — GPIO{n} MCU N1-priority interrupt
0x5A4 MCUN1INT0STAT — Read bits from this register to discover the cause of a recent interrupt.
  [n] MCUN1GPIO{n} (n=0..31) — GPIO{n} MCU N1-priority interrupt
0x5A8 MCUN1INT0CLR — Write a 1 to a bit in this register to clear the interrupt status associated with that bit.
  [n] MCUN1GPIO{n} (n=0..31) — GPIO{n} MCU N1-priority interrupt
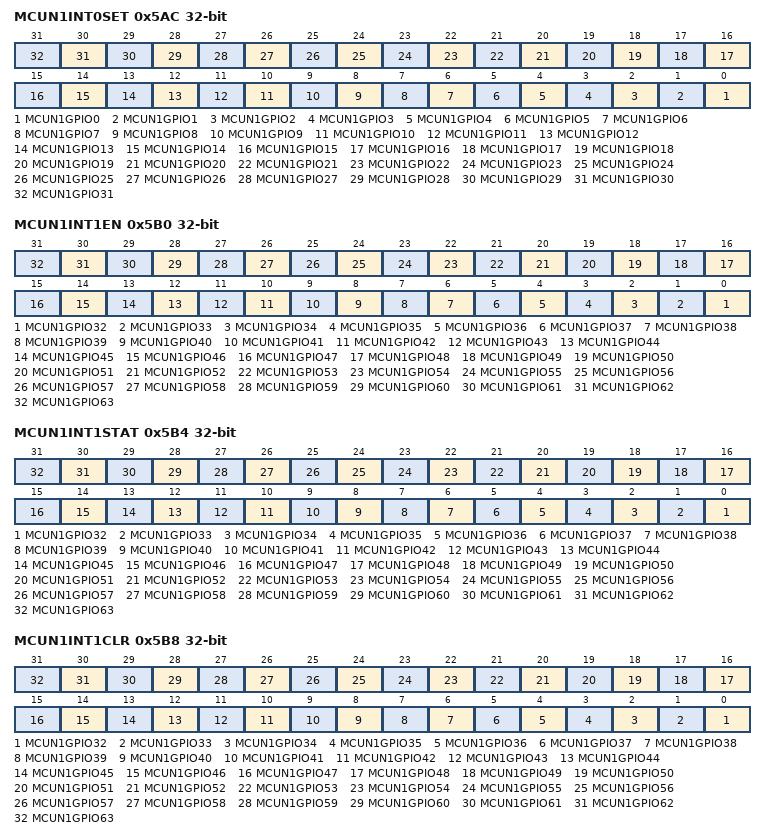
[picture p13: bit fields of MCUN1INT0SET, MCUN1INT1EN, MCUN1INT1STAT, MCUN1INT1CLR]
0x5AC MCUN1INT0SET — Write a 1 to a bit in this register to instantly generate an interrupt from this module. (Generally used for testing purposes).
  [n] MCUN1GPIO{n} (n=0..31) — GPIO{n} MCU N1-priority interrupt
0x5B0 MCUN1INT1EN — Set bits in this register to allow this module to generate the corresponding interrupt.
  [n-32] MCUN1GPIO{n} (n=32..63) — GPIO{n} MCU N1-priority interrupt
0x5B4 MCUN1INT1STAT — Read bits from this register to discover the cause of a recent interrupt.
  [n-32] MCUN1GPIO{n} (n=32..63) — GPIO{n} MCU N1-priority interrupt
0x5B8 MCUN1INT1CLR — Write a 1 to a bit in this register to clear the interrupt status associated with that bit.
  [n-32] MCUN1GPIO{n} (n=32..63) — GPIO{n} MCU N1-priority interrupt
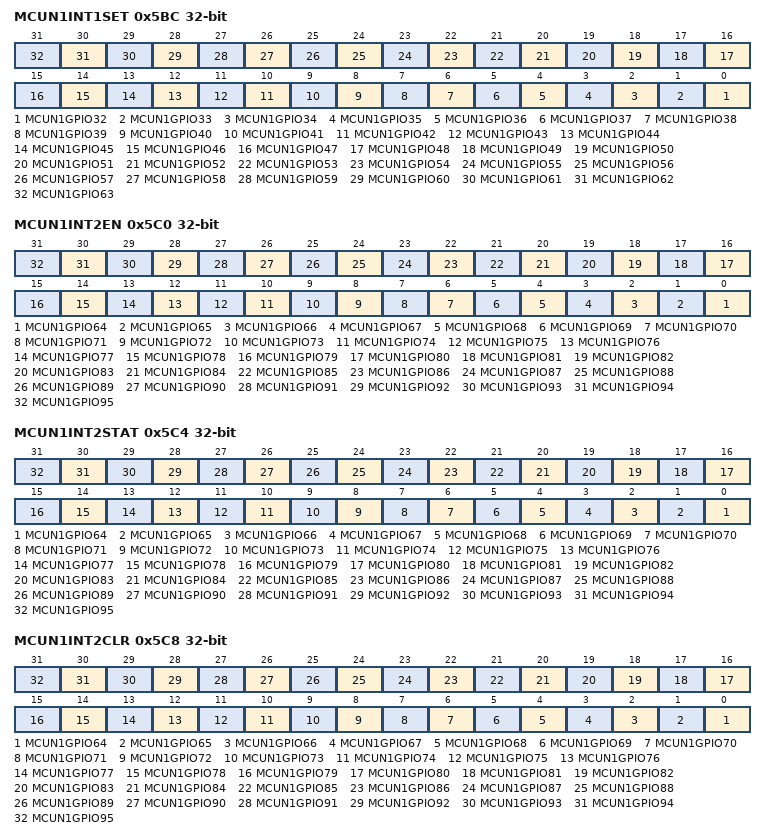
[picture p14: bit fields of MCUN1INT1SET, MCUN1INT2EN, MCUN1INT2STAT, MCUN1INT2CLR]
0x5BC MCUN1INT1SET — Write a 1 to a bit in this register to instantly generate an interrupt from this module. (Generally used for testing purposes).
  [n-32] MCUN1GPIO{n} (n=32..63) — GPIO{n} MCU N1-priority interrupt
0x5C0 MCUN1INT2EN — Set bits in this register to allow this module to generate the corresponding interrupt.
  [n-64] MCUN1GPIO{n} (n=64..95) — GPIO{n} MCU N1-priority interrupt
0x5C4 MCUN1INT2STAT — Read bits from this register to discover the cause of a recent interrupt.
  [n-64] MCUN1GPIO{n} (n=64..95) — GPIO{n} MCU N1-priority interrupt
0x5C8 MCUN1INT2CLR — Write a 1 to a bit in this register to clear the interrupt status associated with that bit.
  [n-64] MCUN1GPIO{n} (n=64..95) — GPIO{n} MCU N1-priority interrupt
0x5CC MCUN1INT2SET — Write a 1 to a bit in this register to instantly generate an interrupt from this module. (Generally used for testing purposes).
  [n-64] MCUN1GPIO{n} (n=64..95) — GPIO{n} MCU N1-priority interrupt
0x5D0 MCUN1INT3EN — Set bits in this register to allow this module to generate the corresponding interrupt.
  [n-96] MCUN1GPIO{n} (n=96..127) — GPIO{n} MCU N1-priority interrupt
0x5D4 MCUN1INT3STAT — Read bits from this register to discover the cause of a recent interrupt.
  [n-96] MCUN1GPIO{n} (n=96..127) — GPIO{n} MCU N1-priority interrupt
0x5D8 MCUN1INT3CLR — Write a 1 to a bit in this register to clear the interrupt status associated with that bit.
  [n-96] MCUN1GPIO{n} (n=96..127) — GPIO{n} MCU N1-priority interrupt
0x5DC MCUN1INT3SET — Write a 1 to a bit in this register to instantly generate an interrupt from this module. (Generally used for testing purposes).
  [n-96] MCUN1GPIO{n} (n=96..127) — GPIO{n} MCU N1-priority interrupt
0x5E0 MCUN1INT4EN — Set bits in this register to allow this module to generate the corresponding interrupt.
  [n-128] MCUN1GPIO{n} (n=128..159) — GPIO{n} MCU N1-priority interrupt
0x5E4 MCUN1INT4STAT — Read bits from this register to discover the cause of a recent interrupt.
  fields as MCUN1INT4EN
0x5E8 MCUN1INT4CLR — Write a 1 to a bit in this register to clear the interrupt status associated with that bit.
  fields as MCUN1INT4EN
0x5EC MCUN1INT4SET — Write a 1 to a bit in this register to instantly generate an interrupt from this module. (Generally used for testing purposes).
  fields as MCUN1INT4EN
0x5F0 MCUN1INT5EN — Set bits in this register to allow this module to generate the corresponding interrupt.
  [n-160] MCUN1GPIO{n} (n=160..191) — GPIO{n} MCU N1-priority interrupt
0x5F4 MCUN1INT5STAT — Read bits from this register to discover the cause of a recent interrupt.
  fields as MCUN1INT5EN
0x5F8 MCUN1INT5CLR — Write a 1 to a bit in this register to clear the interrupt status associated with that bit.
  fields as MCUN1INT5EN
0x5FC MCUN1INT5SET — Write a 1 to a bit in this register to instantly generate an interrupt from this module. (Generally used for testing purposes).
  fields as MCUN1INT5EN
0x600 MCUN1INT6EN — Set bits in this register to allow this module to generate the corresponding interrupt.
  [n-192] MCUN1GPIO{n} (n=192..223) — GPIO{n} MCU N1-priority interrupt
0x604 MCUN1INT6STAT — Read bits from this register to discover the cause of a recent interrupt.
  fields as MCUN1INT6EN
0x608 MCUN1INT6CLR — Write a 1 to a bit in this register to clear the interrupt status associated with that bit.
  fields as MCUN1INT6EN
0x60C MCUN1INT6SET — Write a 1 to a bit in this register to instantly generate an interrupt from this module. (Generally used for testing purposes).
  fields as MCUN1INT6EN
